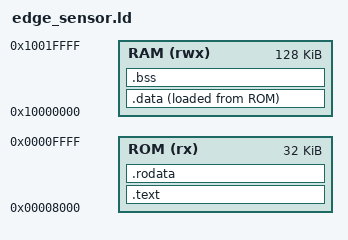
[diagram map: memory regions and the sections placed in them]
/* Auto-generated by Vyges SoC Generator — 2026-04-19T04:46:20Z */
/* Source: soc-spec.yaml -> firmware/edge_sensor.ld */
/* DO NOT EDIT — regenerate with: soc-generator generate soc-spec.yaml */

ENTRY(_start)

MEMORY {
    ROM (rx) : ORIGIN = 0x00008000, LENGTH = 32K
    RAM (rwx) : ORIGIN = 0x10000000, LENGTH = 128K
}

SECTIONS {
    .text : {
        /* Ibex reset fetch is { boot_addr_i[31:8], 8'h80 } per
           ibex_if_stage.sv PC_BOOT case -- so the hart starts at
           ROM+0x80 on reset, not ROM+0x00. Pad the first 128 bytes
           (reserved for an exception vector table in future) and
           place _start at ROM+0x80 so crt0 is actually reachable. */
        . = 0x80;
        KEEP(*(.text.start))
        *(.text*)
    } > ROM

    .rodata : {
        *(.rodata*)
    } > ROM

    /* .data: VMA in RAM, LMA in ROM. crt0 copies
       from _data_lma → _data_start at startup. */
    .data : {
        _data_start = .;
        *(.data*)
        _data_end = .;
    } > RAM AT > ROM
    _data_lma = LOADADDR(.data);

    .bss (NOLOAD) : {
        _bss_start = .;
        *(.bss*)
        *(COMMON)
        _bss_end = .;
    } > RAM

    _stack_top = ORIGIN(RAM) + LENGTH(RAM);
}
